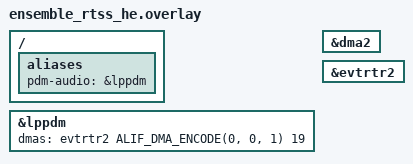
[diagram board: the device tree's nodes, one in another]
/* Copyright (C) 2024 Alif Semiconductor - All Rights Reserved.
 * Use, distribution and modification of this code is permitted under the
 * terms stated in the Alif Semiconductor Software License Agreement
 *
 * You should have received a copy of the Alif Semiconductor Software
 * License Agreement with this file. If not, please write to:
 * contact@alifsemi.com, or visit: https://alifsemi.com/license
 *
 */
/* PDM + DMA */
#include <zephyr/dt-bindings/dma/alif_dma_event_router.h>

/ {
	aliases {
		pdm-audio = &lppdm;
	};
};

&lppdm {
	status = "okay";
	dmas = <&evtrtr2 ALIF_DMA_ENCODE(0, 0, 1) 19>;
	dma-names = "rxdma";
};
&dma2 {
	status = "okay";
};
&evtrtr2 {
	status = "okay";
};

